VERSION ""

NS_ :

BS_: 500

BU_: Vector__XXX

BO_ 2 MSG_002: 8 Vector__XXX
 SG_ Steering_Angle : 48|16@0- (-0.1,0) [-540|540] "��" Vector__XXX

BO_ 209 MSG_0D1: 4 Vector__XXX
 SG_ Brake_Position : 39|9@0+ (0.4,-0.4) [0|100] "%" Vector__XXX

BO_ 212 MSG_0D4: 8 Vector__XXX
 SG_ Wheel_Speed_FL_kph : 0|16@1+ (0.057,0) [0|500] "km/h" Vector__XXX
 SG_ Wheel_Speed_FL_mph : 0|16@1+ (0.035397,0) [0|310.5] "mph" Vector__XXX
 SG_ Wheel_Speed_FR_kph : 16|16@1+ (0.057,0) [0|500] "km/h" Vector__XXX
 SG_ Wheel_Speed_FR_mph : 16|16@1+ (0.035397,0) [0|310.5] "mph" Vector__XXX
 SG_ Wheel_Speed_RL_kph : 32|16@1+ (0.057,0) [0|500] "km/h" Vector__XXX
 SG_ Wheel_Speed_RL_mph : 32|16@1+ (0.035397,0) [0|310.5] "mph" Vector__XXX
 SG_ Wheel_Speed_RR_kph : 48|16@1+ (0.057,0) [0|500] "km/h" Vector__XXX
 SG_ Wheel_Speed_RR_mph : 48|16@1+ (0.035397,0) [0|310.5] "mph" Vector__XXX

BO_ 320 MSG_140: 8 Vector__XXX
 SG_ Engine_Speed : 16|14@1+ (1,0) [0|10000] "rpm" Vector__XXX
 SG_ Accelerator_Pedal_Position : 56|8@0+ (0.392156,0) [0|100] "%" Vector__XXX

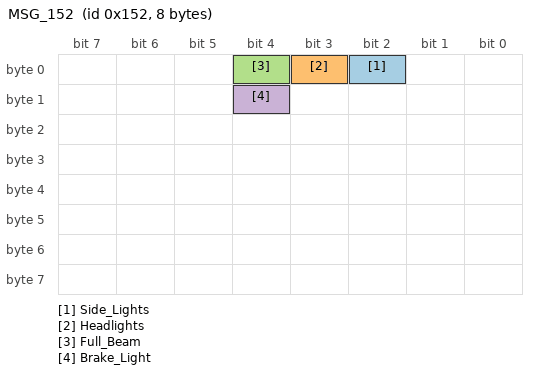
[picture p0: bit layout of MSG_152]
BO_ 338 MSG_152: 8 Vector__XXX
 SG_ Side_Lights : 2|1@0+ (1,0) [0|0] "on/off" Vector__XXX
 SG_ Headlights : 3|1@0+ (1,0) [0|0] "on/off" Vector__XXX
 SG_ Full_Beam : 4|1@0+ (1,0) [0|0] "on/off" Vector__XXX
 SG_ Brake_Light : 12|1@0+ (1,0) [0|0] "on/off" Vector__XXX

BO_ 355 MSG_163: 8 Vector__XXX
 SG_ ACC_Distance : 45|2@0+ (1,0) [0|3] "" Vector__XXX
